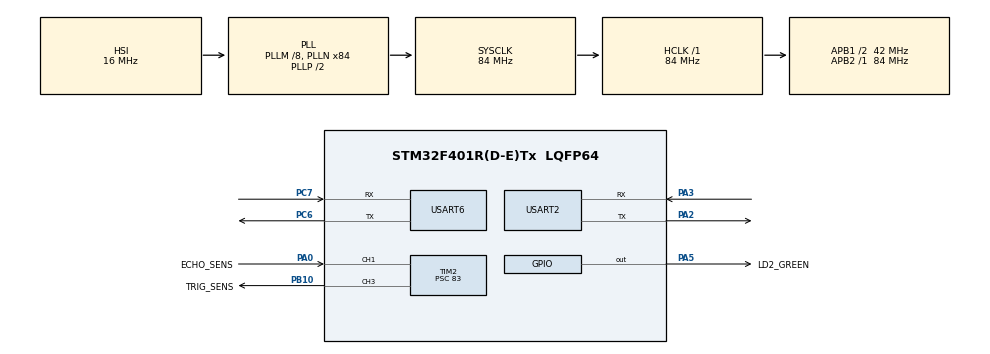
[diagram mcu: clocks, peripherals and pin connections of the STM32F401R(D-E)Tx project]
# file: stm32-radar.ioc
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Mcu.Family=STM32F4
PC15-OSC32_OUT.Mode=LSE-External-Oscillator
RCC.CortexFreq_Value=84000000
TIM2.Channel-Input_Capture1_from_TI1=TIM_CHANNEL_1
PC6.Signal=USART6_TX
RCC.APB1CLKDivider=RCC_HCLK_DIV2
PC14-OSC32_IN.Signal=RCC_OSC32_IN
NVIC.USART2_IRQn=true\:0\:0\:false\:false\:true\:true\:true
RCC.SYSCLKSource=RCC_SYSCLKSOURCE_PLLCLK
ProjectManager.StackSize=0x400
PA0-WKUP.GPIO_Label=ECHO_SENS
PA0-WKUP.Signal=S_TIM2_CH1_ETR
PA3.Mode=Asynchronous
TIM2.ICPolarity_CH1=TIM_INPUTCHANNELPOLARITY_FALLING
ProjectManager.TargetToolchain=STM32CubeIDE
PB10.GPIO_Label=TRIG_SENS
TIM2.Pulse-PWM\ Generation3\ CH3=10
PC6.Mode=Asynchronous
RCC.HCLKFreq_Value=84000000
RCC.APB2TimFreq_Value=84000000
PC7.Signal=USART6_RX
PC15-OSC32_OUT.Signal=RCC_OSC32_OUT
RCC.AHBFreq_Value=84000000
PB10.Signal=S_TIM2_CH3
PA5.Signal=GPIO_Output
RCC.HSE_VALUE=25000000
board=custom
RCC.VCOOutputFreq_Value=168000000
RCC.APB2Freq_Value=84000000
PC14-OSC32_IN.Mode=LSE-External-Oscillator
VP_TIM2_VS_ClockSourceINT.Mode=Internal
SH.S_TIM2_CH3.0=TIM2_CH3,PWM Generation3 CH3
TIM2.Channel-PWM\ Generation3\ CH3=TIM_CHANNEL_3
TIM2.Period=999999
Mcu.Name=STM32F401R(D-E)Tx
PA2.Signal=USART2_TX
RCC.48MHZClocksFreq_Value=42000000
RCC.SYSCLKFreq_VALUE=84000000
Mcu.Package=LQFP64
TIM2.Prescaler=83
PA5.GPIO_Label=LD2_GREEN
USART2.VirtualMode=VM_ASYNC
USART6.VirtualMode=VM_ASYNC
SH.S_TIM2_CH1_ETR.0=TIM2_CH1,Input_Capture1_from_TI1
ProjectManager.HeapSize=0x200
RCC.HSI_VALUE=16000000
NVIC.PriorityGroup=NVIC_PRIORITYGROUP_4
RCC.PLLM=8
RCC.PLLN=84
RCC.APB1TimFreq_Value=84000000
PA2.Mode=Asynchronous
PC7.Mode=Asynchronous
RCC.APB1Freq_Value=42000000
PA3.Signal=USART2_RX

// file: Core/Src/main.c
/* USER CODE BEGIN Header */
/**
 ******************************************************************************
 * @file           : main.c
 * @brief          : Main program body
 ******************************************************************************
 * @attention
 *
 * <h2><center>&copy; Copyright (c) 2022 STMicroelectronics.
 * All rights reserved.</center></h2>
 *
 * This software component is licensed by ST under BSD 3-Clause license,
 * the "License"; You may not use this file except in compliance with the
 * License. You may obtain a copy of the License at:
 *                        opensource.org/licenses/BSD-3-Clause
 *
 ******************************************************************************
 */
/* USER CODE END Header */
#include "main.h"
#include "tim.h"
#include "usart.h"
#include "gpio.h"

/* USER CODE BEGIN Includes */
#include "defines.h"
/* USER CODE END Includes */

void SystemClock_Config(void);

int main(void)
{

  /* MCU Configuration--------------------------------------------------------*/

  /* Reset of all peripherals, Initializes the Flash interface and the Systick. */
  HAL_Init();

  /* Configure the system clock */
  SystemClock_Config();

  /* Initialize all configured peripherals */
  MX_GPIO_Init();
  MX_USART2_UART_Init();
  MX_USART6_UART_Init();
  MX_TIM2_Init();

  /* Infinite loop */
  /* USER CODE BEGIN WHILE */
	HAL_TIM_IC_Start(&htim2, TIM_CHANNEL_1);
	HAL_TIM_PWM_Start(&htim2, TIM_CHANNEL_3);

	while (1) {

		uint32_t value = HAL_TIM_ReadCapturedValue(&htim2, TIM_CHANNEL_1);
		printf("%.1f cm\n", (value - 480) / 58.0f);
		HAL_Delay(1000);

		green_led_tog;
    /* USER CODE END WHILE */

	}
}

void SystemClock_Config(void)
{
  RCC_OscInitTypeDef RCC_OscInitStruct = {0};
  RCC_ClkInitTypeDef RCC_ClkInitStruct = {0};

  /** Configure the main internal regulator output voltage
  */
  __HAL_RCC_PWR_CLK_ENABLE();
  __HAL_PWR_VOLTAGESCALING_CONFIG(PWR_REGULATOR_VOLTAGE_SCALE2);
  /** Initializes the RCC Oscillators according to the specified parameters
  * in the RCC_OscInitTypeDef structure.
  */
  RCC_OscInitStruct.OscillatorType = RCC_OSCILLATORTYPE_HSI;
  RCC_OscInitStruct.HSIState = RCC_HSI_ON;
  RCC_OscInitStruct.HSICalibrationValue = RCC_HSICALIBRATION_DEFAULT;
  RCC_OscInitStruct.PLL.PLLState = RCC_PLL_ON;
  RCC_OscInitStruct.PLL.PLLSource = RCC_PLLSOURCE_HSI;
  RCC_OscInitStruct.PLL.PLLM = 8;
  RCC_OscInitStruct.PLL.PLLN = 84;
  RCC_OscInitStruct.PLL.PLLP = RCC_PLLP_DIV2;
  RCC_OscInitStruct.PLL.PLLQ = 4;
  if (HAL_RCC_OscConfig(&RCC_OscInitStruct) != HAL_OK)
  {
    Error_Handler();
  }
  /** Initializes the CPU, AHB and APB buses clocks
  */
  RCC_ClkInitStruct.ClockType = RCC_CLOCKTYPE_HCLK|RCC_CLOCKTYPE_SYSCLK
                              |RCC_CLOCKTYPE_PCLK1|RCC_CLOCKTYPE_PCLK2;
  RCC_ClkInitStruct.SYSCLKSource = RCC_SYSCLKSOURCE_PLLCLK;
  RCC_ClkInitStruct.AHBCLKDivider = RCC_SYSCLK_DIV1;
  RCC_ClkInitStruct.APB1CLKDivider = RCC_HCLK_DIV2;
  RCC_ClkInitStruct.APB2CLKDivider = RCC_HCLK_DIV1;

  if (HAL_RCC_ClockConfig(&RCC_ClkInitStruct, FLASH_LATENCY_2) != HAL_OK)
  {
    Error_Handler();
  }
}

/* USER CODE BEGIN 4 */
int __io_putchar(int ch) {
	if (ch == '\n') {
		__io_putchar('\r');
	}

	HAL_UART_Transmit(&huart2, (uint8_t*) &ch, 1, HAL_MAX_DELAY);

	return 1;
}
/* USER CODE END 4 */

void Error_Handler(void)
{
	__disable_irq();
	while (1) {
	}
}

/************************ (C) COPYRIGHT STMicroelectronics *****END OF FILE****/
